# LPC11Axx register map
File version: 0.6
CPU: CM0 r0p0, little endian, no MPU, no FPU, 0x2 interrupt priority bits, 0x0 interrupts
Registers are 32-bit, read-write, reset 0x0 unless marked. A register's access mark holds for its fields unless they carry their own. Offsets are from the block's base; [hi:lo] are bit positions; {n}, {i} and the like mark numbered series.

## DAC
Base 0x40024000
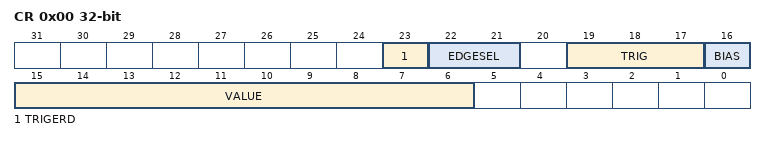
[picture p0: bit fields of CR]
0x00 CR — D/A control register
  [23] TRIGERD — If the TRIG field (above) is non-zero, this bit is set when a conversion is triggered, and is cleared by any write to this register.
  [22:21] EDGESEL — For non-zero values of TRIG, this field selects when the conversion is triggered:
    0=FALLING (Falling edges); 1=RISINGs (Rising edges); 2=DUALEDGE (Both edges); 3=DUALEDGE (Both edges)
  [19:17] TRIG — The value written to this field determines whether conversion begins immediately after this register is written, or whether conversion is delayed until a selected event occurs.
    0=IMMEDIATE (Conversion begins when this register is written, and AOUT begins to change to the new voltage immediately. For all other values in this field, AOUT remains at its previous voltage until the selected event has occurred.); 1=COMPLEVELOUT (Conversion is triggered by the selected edge(s) on the analog comparator (level) output); 2=ATRG0EDGE (Conversion is triggered by the selected edge(s) on ATRG0.); 3=ATRG1EDGE (Conversion is triggered by the selected edge(s) on ATRG1.); 4=CT32B1_MAT0EDGE (Conversion is triggered by the selected edge(s) on CT32B1_MAT0 [2].); 5=CT32B1_MAT1EDGE (Conversion is triggered by the selected edge(s) on CT32B1_MAT1[2].); 6=CT16B1_MAT0EDGE (Conversion is triggered by the selected edge(s) on CT16B1_MAT0[2].); 7=CT16B1_MAT1EDGE (Conversion is triggered by the selected edge(s) on CT16B1_MAT1[2].)
  [16] BIAS — Settling time
    0=FAST (The settling time of the DAC is 1 us max, and the maximum current is 700 uA. This allows a maximum update rate of 1 MHz.); 1=SLOW (The settling time of the DAC is 2.5 us and the maximum current is 350 uA. This allows a maximum update rate of 400 kHz.)
  [15:6] VALUE — After the selected settling time after a conversion begins, the voltage on the AOUT pin (with respect to VSS) is VALUE x (V DD/1024).

## CMP — Comparator
Base 0x40028000
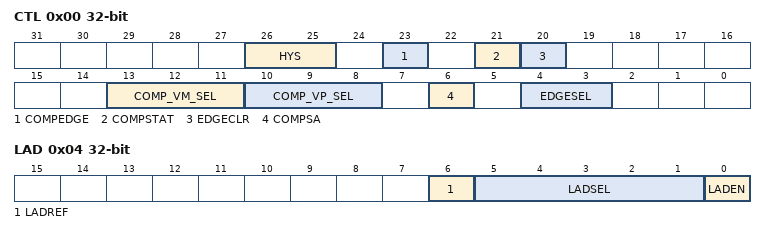
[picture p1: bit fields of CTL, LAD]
0x00 CTL — Comparator control register
  [26:25] HYS — Controls the hysteresis of the comparator. When the comparator is outputting a certain state, this is the difference between the selected signals, in the opposite direction from the state being output, that will switch the output.
    0=NOHYSTERESIS (None (the output will switch as the voltages cross)); 1=HYS5MV (5 mV); 2=HSY10MV (10 mV); 3=HSY20MV (20 mV)
  [23] COMPEDGE — Comparator edge-detect status.
  [21] COMPSTAT — Comparator status. This bit reflects the state of the comparator output.
  [20] EDGECLR — Interrupt clear bit. Writing a 1 to this bit clears the COMPEDGE bit (bit 23 below) and thus negates the interrupt request.
  [13:11] COMP_VM_SEL — Selects negative voltage input
    0=VLADDOUT (voltage ladder output); {v}=ACMPI{v} (v=1..5); 6=INTVOLTAGEREF (internal reference voltage)
  [10:8] COMP_VP_SEL — Selects positive voltage input
    0=VLADOUT (voltage ladder output); {v}=ACMPI{v} (v=1..5); 6=INTVOLTAGEREF (internal reference voltage); 7=TEMPSENSOR (temperature sensor)
  [6] COMPSA — Comarator output control
    0=DIRECT (Uses the comparator output directly.); 1=SYNCH (Synchronizes the comparator output to the bus clock for output to other modules.)
  [4:3] EDGESEL — This field controls which edges on the comparator output set the COMPEDGE bit (bit 23 below): 00 = Falling edges 01 = Rising edges 1x = Both edges
    0=FALLING (Falling edges); 1=RISING (Rising edges); 2=DUALEDGE (Both edges); 3=DUALEDGE (Both edges)
0x04 LAD — Voltage ladder register
  [6] LADREF — Selects the reference voltage for the voltage ladder
    0=VDDPIN; 1=VDDCMPPIN
  [5:1] LADSEL — Voltage ladder value. The reference voltage Vref depends on the LADREF bit below. 00000 = VSS 00001 = 1 Vref/31 00010 = 2 Vref/31 ... 11111 = Vref
  [0] LADEN — Voltage ladder enable
